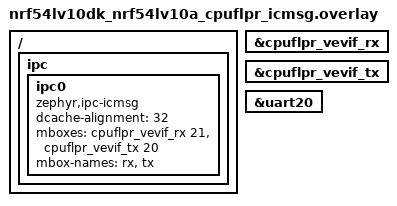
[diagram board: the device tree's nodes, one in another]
/*
 * Copyright (c) 2025 Nordic Semiconductor ASA
 *
 * SPDX-License-Identifier: LicenseRef-Nordic-5-Clause
 */

/ {
	ipc {
		ipc0: ipc0 {
			compatible = "zephyr,ipc-icmsg";
			dcache-alignment = <32>;
			/delete-property/ tx-blocks;
			/delete-property/ rx-blocks;
			mboxes = <&cpuflpr_vevif_rx 21>, <&cpuflpr_vevif_tx 20>;
			mbox-names = "rx", "tx";
			status = "okay";
		};
	};
};

&cpuflpr_vevif_rx {
	status = "okay";
};

&cpuflpr_vevif_tx {
	status = "okay";
};

&uart20 {
	/delete-property/ hw-flow-control;
};
